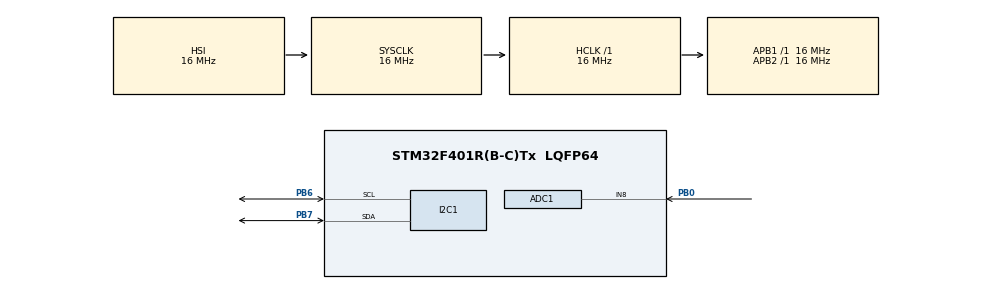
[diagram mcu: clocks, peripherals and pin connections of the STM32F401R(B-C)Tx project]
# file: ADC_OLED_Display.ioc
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ADC1.Channel-0\#ChannelRegularConversion=ADC_CHANNEL_8
ADC1.NbrOfConversionFlag=1
ADC1.Rank-0\#ChannelRegularConversion=1
ADC1.SamplingTime-0\#ChannelRegularConversion=ADC_SAMPLETIME_3CYCLES
ADC1.master=1
Mcu.Family=STM32F4
Mcu.Name=STM32F401R(B-C)Tx
Mcu.Package=LQFP64
NVIC.PriorityGroup=NVIC_PRIORITYGROUP_4
PA13.Mode=Serial_Wire
PA13.Signal=SYS_JTMS-SWDIO
PA14.Mode=Serial_Wire
PA14.Signal=SYS_JTCK-SWCLK
PB0.Signal=ADCx_IN8
PB6.Mode=I2C
PB6.Signal=I2C1_SCL
PB7.Mode=I2C
PB7.Signal=I2C1_SDA
ProjectManager.HeapSize=0x200
ProjectManager.StackSize=0x400
ProjectManager.TargetToolchain=STM32CubeIDE
RCC.AHBFreq_Value=16000000
RCC.APB1Freq_Value=16000000
RCC.APB2Freq_Value=16000000
RCC.CortexFreq_Value=16000000
RCC.HSE_VALUE=25000000
RCC.HSI_VALUE=16000000
RCC.LSE_VALUE=32768
RCC.SYSCLKFreq_VALUE=16000000
RCC.VCOOutputFreq_Value=192000000
SH.ADCx_IN8.0=ADC1_IN8,IN8
board=custom

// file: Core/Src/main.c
/* USER CODE BEGIN Header */
/**
  ******************************************************************************
  * @file           : main.c
  * @brief          : Main program body
  ******************************************************************************
  * @attention
  *
  * Copyright (c) 2026 STMicroelectronics.
  * All rights reserved.
  *
  * This software is licensed under terms that can be found in the LICENSE file
  * in the root directory of this software component.
  * If no LICENSE file comes with this software, it is provided AS-IS.
  *
  ******************************************************************************
  */
/* USER CODE END Header */
#include "main.h"

/* USER CODE BEGIN Includes */
#include <stdio.h>
#include "ssd1306.h"
#include "ssd1306_fonts.h"
/* USER CODE END Includes */

ADC_HandleTypeDef hadc1;

I2C_HandleTypeDef hi2c1;

/* USER CODE BEGIN PV */
volatile uint32_t adc_value = 0;
float voltage = 0.0f;
char oled_text[32];
/* USER CODE END PV */

void SystemClock_Config(void);
static void MX_GPIO_Init(void);
static void MX_ADC1_Init(void);
static void MX_I2C1_Init(void);

int main(void)
{

  /* MCU Configuration--------------------------------------------------------*/

  /* Reset of all peripherals, Initializes the Flash interface and the Systick. */
  HAL_Init();

  /* Configure the system clock */
  SystemClock_Config();

  /* Initialize all configured peripherals */
  MX_GPIO_Init();
  MX_ADC1_Init();
  MX_I2C1_Init();
  /* USER CODE BEGIN 2 */
  ssd1306_Init();
  ssd1306_Fill(Black);
  ssd1306_UpdateScreen();

  /* USER CODE END 2 */

  /* Infinite loop */
  /* USER CODE BEGIN WHILE */
  while (1)
  {
	  HAL_ADC_Start(&hadc1);

	      if (HAL_ADC_PollForConversion(&hadc1, 100) == HAL_OK)
	      {
	          adc_value = HAL_ADC_GetValue(&hadc1);

	          voltage = ((float)adc_value * 3.3f) / 4095.0f;

	          ssd1306_Fill(Black);

	          snprintf(
	              oled_text,
	              sizeof(oled_text),
	              "ADC: %lu",
	              (unsigned long)adc_value
	          );

	          ssd1306_SetCursor(5, 15);
	          ssd1306_WriteString(oled_text, Font_7x10, White);

	          snprintf(oled_text, sizeof(oled_text),"Volt: %.2f V",voltage);

	          ssd1306_SetCursor(5, 35);
	          ssd1306_WriteString(oled_text, Font_7x10, White);

	          ssd1306_UpdateScreen();
	      }

	      HAL_ADC_Stop(&hadc1);
	      HAL_Delay(100);
    /* USER CODE END WHILE */

  }
}

void SystemClock_Config(void)
{
  RCC_OscInitTypeDef RCC_OscInitStruct = {0};
  RCC_ClkInitTypeDef RCC_ClkInitStruct = {0};

  /** Configure the main internal regulator output voltage
  */
  __HAL_RCC_PWR_CLK_ENABLE();
  __HAL_PWR_VOLTAGESCALING_CONFIG(PWR_REGULATOR_VOLTAGE_SCALE2);

  /** Initializes the RCC Oscillators according to the specified parameters
  * in the RCC_OscInitTypeDef structure.
  */
  RCC_OscInitStruct.OscillatorType = RCC_OSCILLATORTYPE_HSI;
  RCC_OscInitStruct.HSIState = RCC_HSI_ON;
  RCC_OscInitStruct.HSICalibrationValue = RCC_HSICALIBRATION_DEFAULT;
  RCC_OscInitStruct.PLL.PLLState = RCC_PLL_NONE;
  if (HAL_RCC_OscConfig(&RCC_OscInitStruct) != HAL_OK)
  {
    Error_Handler();
  }

  /** Initializes the CPU, AHB and APB buses clocks
  */
  RCC_ClkInitStruct.ClockType = RCC_CLOCKTYPE_HCLK|RCC_CLOCKTYPE_SYSCLK
                              |RCC_CLOCKTYPE_PCLK1|RCC_CLOCKTYPE_PCLK2;
  RCC_ClkInitStruct.SYSCLKSource = RCC_SYSCLKSOURCE_HSI;
  RCC_ClkInitStruct.AHBCLKDivider = RCC_SYSCLK_DIV1;
  RCC_ClkInitStruct.APB1CLKDivider = RCC_HCLK_DIV1;
  RCC_ClkInitStruct.APB2CLKDivider = RCC_HCLK_DIV1;

  if (HAL_RCC_ClockConfig(&RCC_ClkInitStruct, FLASH_LATENCY_0) != HAL_OK)
  {
    Error_Handler();
  }
}

static void MX_ADC1_Init(void)
{

  ADC_ChannelConfTypeDef sConfig = {0};

  /** Configure the global features of the ADC (Clock, Resolution, Data Alignment and number of conversion)
  */
  hadc1.Instance = ADC1;
  hadc1.Init.ClockPrescaler = ADC_CLOCK_SYNC_PCLK_DIV2;
  hadc1.Init.Resolution = ADC_RESOLUTION_12B;
  hadc1.Init.ScanConvMode = DISABLE;
  hadc1.Init.ContinuousConvMode = DISABLE;
  hadc1.Init.DiscontinuousConvMode = DISABLE;
  hadc1.Init.ExternalTrigConvEdge = ADC_EXTERNALTRIGCONVEDGE_NONE;
  hadc1.Init.ExternalTrigConv = ADC_SOFTWARE_START;
  hadc1.Init.DataAlign = ADC_DATAALIGN_RIGHT;
  hadc1.Init.NbrOfConversion = 1;
  hadc1.Init.DMAContinuousRequests = DISABLE;
  hadc1.Init.EOCSelection = ADC_EOC_SINGLE_CONV;
  if (HAL_ADC_Init(&hadc1) != HAL_OK)
  {
    Error_Handler();
  }

  /** Configure for the selected ADC regular channel its corresponding rank in the sequencer and its sample time.
  */
  sConfig.Channel = ADC_CHANNEL_8;
  sConfig.Rank = 1;
  sConfig.SamplingTime = ADC_SAMPLETIME_3CYCLES;
  if (HAL_ADC_ConfigChannel(&hadc1, &sConfig) != HAL_OK)
  {
    Error_Handler();
  }

}

static void MX_I2C1_Init(void)
{

  hi2c1.Instance = I2C1;
  hi2c1.Init.ClockSpeed = 100000;
  hi2c1.Init.DutyCycle = I2C_DUTYCYCLE_2;
  hi2c1.Init.OwnAddress1 = 0;
  hi2c1.Init.AddressingMode = I2C_ADDRESSINGMODE_7BIT;
  hi2c1.Init.DualAddressMode = I2C_DUALADDRESS_DISABLE;
  hi2c1.Init.OwnAddress2 = 0;
  hi2c1.Init.GeneralCallMode = I2C_GENERALCALL_DISABLE;
  hi2c1.Init.NoStretchMode = I2C_NOSTRETCH_DISABLE;
  if (HAL_I2C_Init(&hi2c1) != HAL_OK)
  {
    Error_Handler();
  }

}

static void MX_GPIO_Init(void)
{

  /* GPIO Ports Clock Enable */
  __HAL_RCC_GPIOB_CLK_ENABLE();
  __HAL_RCC_GPIOA_CLK_ENABLE();

}

void Error_Handler(void)
{
  __disable_irq();
  while (1)
  {
  }
}
